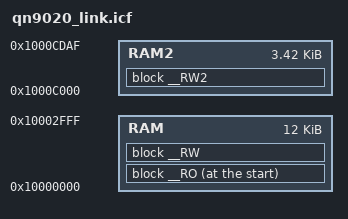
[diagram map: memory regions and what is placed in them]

// define
define symbol RAM_BEGIN  = 0x10000000;
define symbol RAM_SIZE   = 0x3000;
define symbol RAM_BEGIN2 = 0x1000C000;
define symbol RAM_SIZE2  = 0xDB0;
define symbol STACK_SIZE = 0x100;
define symbol HEAP_SIZE  = 0x0;

// config
initialize by copy with packing = none { readwrite };
do not initialize  { section .noinit };

define memory MEM with size = 4G;
define region RAM =  MEM:[from RAM_BEGIN size RAM_SIZE];
define region RAM2 = MEM:[from RAM_BEGIN2 size RAM_SIZE2];

define block CSTACK    with alignment = 8, size = STACK_SIZE { };
define block HEAP      with alignment = 8, size = HEAP_SIZE  { };

define block __RO with fixed order
{
    readonly section .intvec,
    readonly section .RESET,
    readonly,
};

define block __RW 
{   
    readwrite,
    block CSTACK,
    block HEAP
};

define block __RW2
{   
    readonly object app_env.o
    readonly object app_gap.o 
    readonly object app_gap_task.o 
    readonly object button.o 
    readonly object app_smp_task.o 
    readonly object app_task.o 
    readonly object app_util.o 
    readonly object prf_utils.o 
    readonly object wdt.o 
    readonly object system.o 
    readonly object timer.o 
    readonly object usr_design.o 
    readonly object gpio.o 
    readonly object led.o
};

place at start of RAM {block __RO};

place in RAM {block __RW};

place in RAM2 {block __RW2};

